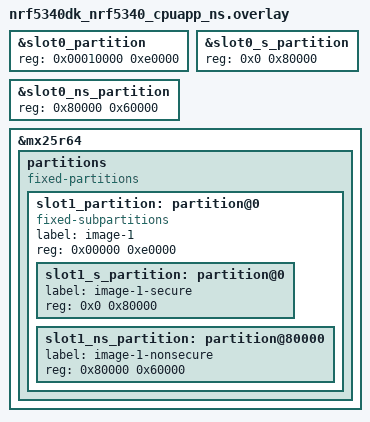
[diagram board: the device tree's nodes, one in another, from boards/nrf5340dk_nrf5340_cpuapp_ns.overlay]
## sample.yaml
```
sample:
  description: nRF Connect SDK Intermediate Course by Nordic Developer Academy (https://academy.nordicsemi.com/)
  name: nRF Connect SDK Intermediate Course - Lesson 9 Exercise 3 Solution
  
common: 
    sysbuild: true
    build_only: true
    
    integration_platforms: 
      - nrf52840dk/nrf52840
      - nrf7002dk/nrf5340/cpuapp
      - nrf7002dk/nrf5340/cpuapp/ns
      - nrf5340dk/nrf5340/cpuapp
      - nrf5340dk/nrf5340/cpuapp/ns
      - nrf54l15dk/nrf54l15/cpuapp
      - nrf54lc10dk/nrf54lc10a/cpuapp
      - nrf54lm20dk/nrf54lm20a/cpuapp
      - nrf9151dk/nrf9151/ns
      - nrf9151dk/nrf9151
      - nrf9160dk/nrf9160/ns
      - nrf9160dk/nrf9160
      - nrf9161dk/nrf9161/ns
      - nrf9161dk/nrf9161
    platform_allow:
      - nrf52840dk/nrf52840
      - nrf7002dk/nrf5340/cpuapp
      - nrf7002dk/nrf5340/cpuapp/ns
      - nrf5340dk/nrf5340/cpuapp
      - nrf5340dk/nrf5340/cpuapp/ns
      - nrf54l15dk/nrf54l15/cpuapp
      - nrf54lc10dk/nrf54lc10a/cpuapp
      - nrf54lm20dk/nrf54lm20a/cpuapp
      - nrf9151dk/nrf9151/ns
      - nrf9151dk/nrf9151
      - nrf9160dk/nrf9160/ns
      - nrf9160dk/nrf9160
      - nrf9161dk/nrf9161/ns
      - nrf9161dk/nrf9161

    
tests:
  ncs_inter.l9.e3.sol: {}
```

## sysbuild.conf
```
# MCUboot
SB_CONFIG_BOOTLOADER_MCUBOOT=y

SB_CONFIG_PARTITION_MANAGER=n
```

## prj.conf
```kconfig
CONFIG_GPIO=y

# Enable mcumgr DFU in application
CONFIG_MCUMGR=y
CONFIG_UART_MCUMGR=y
CONFIG_MCUMGR_TRANSPORT_UART=y

# Enable MCUMGR management for both OS and Images
CONFIG_MCUMGR_GRP_OS=y
CONFIG_MCUMGR_GRP_IMG=y

# Configure MCUMGR transport to UART
CONFIG_MCUMGR_TRANSPORT_UART=y

# Dependencies
# Configure dependencies for CONFIG_MCUMGR  
CONFIG_NET_BUF=y
CONFIG_ZCBOR=y
CONFIG_CRC=y

# Configure dependencies for CONFIG_MCUMGR_GRP_IMG  
CONFIG_FLASH=y
CONFIG_IMG_MANAGER=y

# Configure dependencies for CONFIG_IMG_MANAGER  
CONFIG_STREAM_FLASH=y
CONFIG_FLASH_MAP=y

# Configure dependencies for CONFIG_MCUMGR_TRANSPORT_UART 
CONFIG_BASE64=y
```

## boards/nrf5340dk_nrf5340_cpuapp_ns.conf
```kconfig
# STEP 1.1 - Enable QSPI driver for Application
CONFIG_NORDIC_QSPI_NOR=y
```

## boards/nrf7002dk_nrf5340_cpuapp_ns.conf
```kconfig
# STEP 1.1 - Enable SPI driver for Application
CONFIG_GPIO=y
CONFIG_SPI=y
CONFIG_SPI_NOR=y
CONFIG_SPI_NOR_SFDP_DEVICETREE=y
CONFIG_SPI_NOR_FLASH_LAYOUT_PAGE_SIZE=4096
# QSPI drivers are enabled by defualt for some chips.
# Disable it explicitly to be sure QSPI is disabled.
CONFIG_NORDIC_QSPI_NOR=n 

# required by SPI driver
CONFIG_MULTITHREADING=y
```

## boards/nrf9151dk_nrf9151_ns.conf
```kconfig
# STEP 1.1 - Enable SPI driver for Application
CONFIG_GPIO=y
CONFIG_SPI=y
CONFIG_SPI_NOR=y
CONFIG_SPI_NOR_SFDP_DEVICETREE=y
CONFIG_SPI_NOR_FLASH_LAYOUT_PAGE_SIZE=4096
# QSPI drivers are enabled by defualt for some chips.
# Disable it explicitly to be sure QSPI is disabled.
CONFIG_NORDIC_QSPI_NOR=n 

# required by SPI driver
CONFIG_MULTITHREADING=y

# Minimal TF-M profile required by the no-bootloader partition layout
CONFIG_TFM_PROFILE_TYPE_MINIMAL=y
```

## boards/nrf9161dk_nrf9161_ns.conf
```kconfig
CONFIG_GPIO=y
CONFIG_SPI=y
CONFIG_SPI_NOR=y
CONFIG_SPI_NOR_SFDP_DEVICETREE=y
CONFIG_SPI_NOR_FLASH_LAYOUT_PAGE_SIZE=4096
# QSPI drivers are enabled by defualt for some chips.
# Disable it explicitly to be sure QSPI is disabled.
CONFIG_NORDIC_QSPI_NOR=n 

# required by SPI driver
CONFIG_MULTITHREADING=y

# Minimal TF-M profile required by the no-bootloader partition layout
CONFIG_TFM_PROFILE_TYPE_MINIMAL=y
```

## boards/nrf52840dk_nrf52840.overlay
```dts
/*
 * Copyright (c) 2020 Nordic Semiconductor ASA
 *
 * SPDX-License-Identifier: Apache-2.0
 */

/delete-node/ &boot_partition;
/delete-node/ &slot0_partition;
/delete-node/ &slot1_partition;

&flash0 {
	partitions {

		ranges;
		#address-cells = <1>;
		#size-cells = <1>;

		boot_partition: partition@0 {
			compatible = "zephyr,mapped-partition";
			label = "mcuboot";
			reg = <0x000000000 0x00010000>;
		};

		slot0_partition: partition@10000 {
			compatible = "zephyr,mapped-partition";
			label = "image-0";
			reg = <0x000010000 0x0000e8000>;
		};
	};
};

/* STEP 2.1 - Add external flash to board conf file */
&mx25r64 {
	partitions {
		compatible = "fixed-partitions";
		#address-cells = <1>;
		#size-cells = <1>;

		slot1_partition: partition@0 {
			label = "image-1";
			reg = <0x000000000 0x0000e8000>;
		};
	};
};
```

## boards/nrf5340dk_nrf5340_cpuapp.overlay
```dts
/delete-node/ &slot1_partition;
/delete-node/ &slot0_partition;
/delete-node/ &storage_partition;

&flash0 {
	partitions {
		ranges;
		#address-cells = <1>;
		#size-cells = <1>;

		boot_partition: partition@0 {
			compatible = "zephyr,mapped-partition";
			label = "mcuboot";
			reg = <0x00000000 0x10000>;
		};

		slot0_partition: partition@10000 {
			compatible = "zephyr,mapped-partition";
			label = "image-0";
			reg = <0x00010000 0xe0000>;
		};
	};
};

/* STEP 2.1 - Add external flash to board conf file */
&mx25r64 {
	partitions {
		compatible = "fixed-partitions";
		#address-cells = <1>;
		#size-cells = <1>;

		slot1_partition: partition@0 {
			label = "image-1";
			reg = <0x00000 0xe0000>;
		};
	};
};
```

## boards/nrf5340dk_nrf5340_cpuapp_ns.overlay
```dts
/delete-node/ &slot1_partition;

&slot0_partition {
	reg = <0x00010000 0xe0000>;
	ranges = <0x0 0x10000 0xe0000>;
};

&slot0_s_partition {
	reg = <0x0 0x80000>;
};

&slot0_ns_partition {
	reg = <0x80000 0x60000>;
};

/* STEP 2.1 - Add external flash to board conf file */
&mx25r64 {
	partitions {
		compatible = "fixed-partitions";
		#address-cells = <1>;
		#size-cells = <1>;

		slot1_partition: partition@0 {
			compatible = "fixed-subpartitions";
			label = "image-1";
			reg = <0x00000 0xe0000>;
			#address-cells = <1>;
			#size-cells = <1>;

			slot1_s_partition: partition@0 {
				label = "image-1-secure";
				reg = <0x0 0x80000>;
			};

			slot1_ns_partition: partition@80000 {
				label = "image-1-nonsecure";
				reg = <0x80000 0x60000>;
			};
		};
	};
};
```

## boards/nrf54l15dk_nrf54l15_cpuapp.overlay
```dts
/delete-node/ &boot_partition;
/delete-node/ &slot0_partition;
/delete-node/ &slot1_partition;


&cpuapp_rram {
    partitions {
        boot_partition: partition@0 {
            compatible = "zephyr,mapped-partition";
            label = "mcuboot";
            reg = <0x0 DT_SIZE_K(100)>;
        };

        slot0_partition: partition@19000 {
            compatible = "zephyr,mapped-partition";
            label = "image-0";
            reg = <0x19000 DT_SIZE_K(1200)>;
        };
    };
};

/* STEP 2.1 - Add external flash to board conf file */
&mx25r64 {
    status = "okay";
    partitions {
        compatible = "fixed-partitions";
        #address-cells = <1>;
        #size-cells = <1>;

        slot1_partition: partition@0 {
            label = "image-1";
            reg = <0x0 DT_SIZE_K(1200)>;
        };
    };
};
```

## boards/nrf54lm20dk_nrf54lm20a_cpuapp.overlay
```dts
/delete-node/ &boot_partition;
/delete-node/ &slot0_partition;
/delete-node/ &slot1_partition;


&cpuapp_rram {
    partitions {
        boot_partition: partition@0 {
            compatible = "zephyr,mapped-partition";
            label = "mcuboot";
            reg = <0x0 DT_SIZE_K(100)>;
        };

        slot0_partition: partition@19000 {
            compatible = "zephyr,mapped-partition";
            label = "image-0";
            reg = <0x19000 DT_SIZE_K(1536)>;
        };
    };
};

/* STEP 2.1 - Add external flash to board conf file */
&mx25r64 {
    status = "okay";
    partitions {
        compatible = "fixed-partitions";
        #address-cells = <1>;
        #size-cells = <1>;

        slot1_partition: partition@0 {
            label = "image-1";
            reg = <0x0 DT_SIZE_K(1536)>;
        };
    };
};
```

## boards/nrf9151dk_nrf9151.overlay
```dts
/delete-node/ &slot1_partition;



&gd25wb256 {
    status = "okay";
    partitions {
        compatible = "fixed-partitions";
        #address-cells = <1>;
        #size-cells = <1>;

        slot1_partition: partition@80000 {
            compatible = "fixed-subpartitions";
            label = "image-1";
            reg = <0x80000 0x70000>;
            #address-cells = <1>;
            #size-cells = <1>;

            slot1_s_partition: partition@0 {
                label = "image-1-secure";
                reg = <0x0 0x40000>;
            };

            slot1_ns_partition: partition@40000 {
                label = "image-1-nonsecure";
                reg = <0x40000 0x30000>;
            };
        };
    };
};
```

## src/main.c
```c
/*
 * Copyright (c) 2016 Intel Corporation
 *
 * SPDX-License-Identifier: Apache-2.0
 */

#include <zephyr/kernel.h>
#include <zephyr/drivers/gpio.h>

/* 1000 msec = 1 sec */

#define SLEEP_TIME_MS   100

/* The devicetree node identifier for the "led0" alias. */
#define LED0_NODE DT_ALIAS(led0)

/*
 * A build error on this line means your board is unsupported.
 * See the sample documentation for information on how to fix this.
 */
static const struct gpio_dt_spec led = GPIO_DT_SPEC_GET(LED0_NODE, gpios);

int main(void)
{
	int ret;

	if (!device_is_ready(led.port)) {
		return -1;
	}

	ret = gpio_pin_configure_dt(&led, GPIO_OUTPUT_ACTIVE);
	if (ret < 0) {
		return -1;
	}

	while (1) {
		ret = gpio_pin_toggle_dt(&led);
		if (ret < 0) {
			return -1;
		}
		k_msleep(SLEEP_TIME_MS);
	}
}
```
